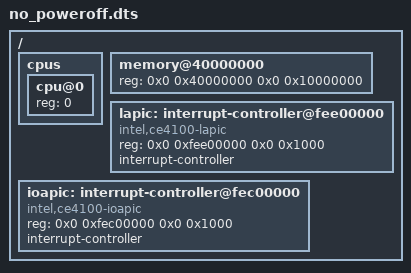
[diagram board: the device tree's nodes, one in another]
/dts-v1/;

/ {
	#address-cells = <2>;
	#size-cells = <2>;

	cpus {
		#address-cells = <1>;
		#size-cells = <0>;
		cpu@0 {
			device_type = "cpu";
			reg = <0>;
		};
	};

	memory@40000000 {
		device_type = "memory";
		reg = <0x0 0x40000000 0x0 0x10000000>;
	};

	lapic: interrupt-controller@fee00000 {
		compatible = "intel,ce4100-lapic";
		reg = <0x0 0xfee00000 0x0 0x1000>;
		interrupt-controller;
		#interrupt-cells = <2>;
	};

	ioapic: interrupt-controller@fec00000 {
		compatible = "intel,ce4100-ioapic";
		reg = <0x0 0xfec00000 0x0 0x1000>;
		interrupt-controller;
		#interrupt-cells = <2>;
	};
};
